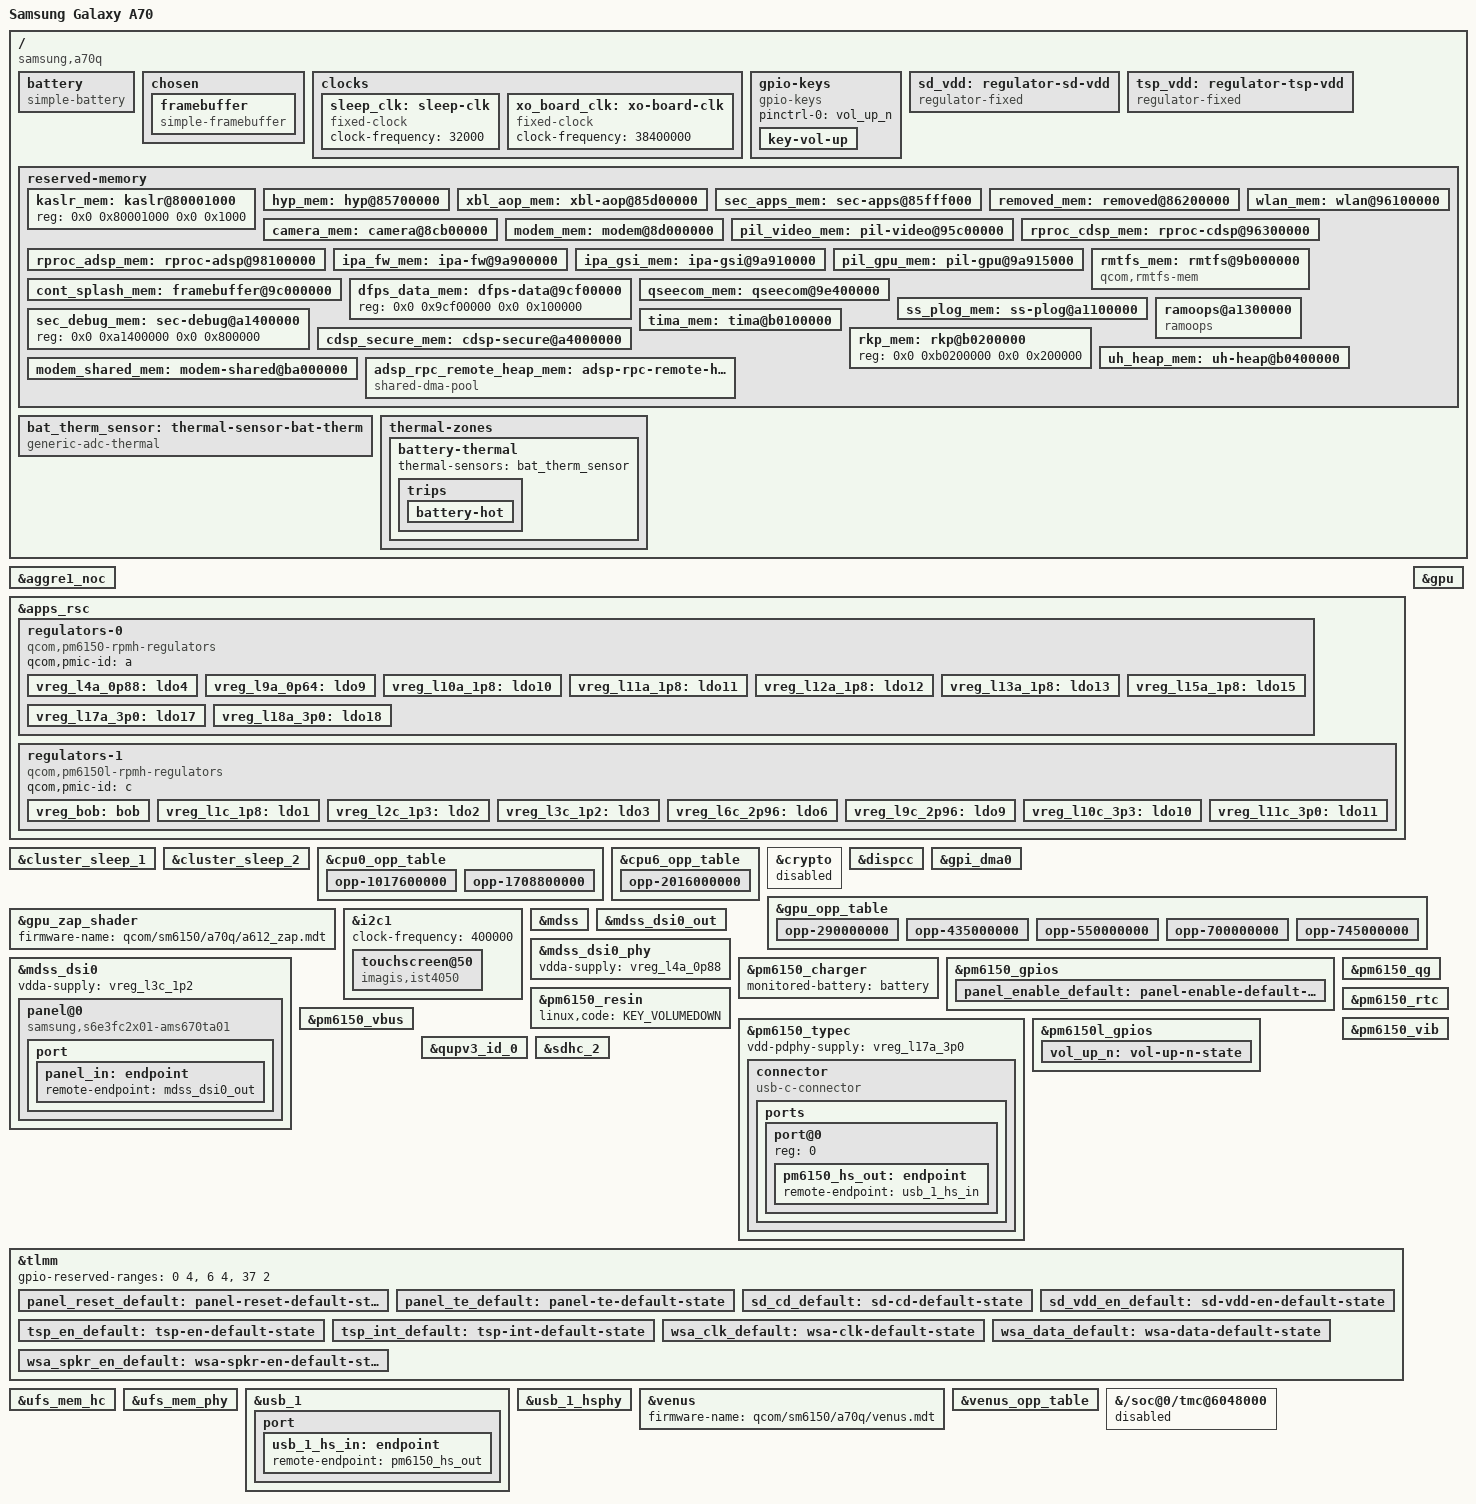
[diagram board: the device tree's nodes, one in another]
// SPDX-License-Identifier: BSD-3-Clause

/dts-v1/;

#include <dt-bindings/firmware/qcom,scm.h>
#include <dt-bindings/gpio/gpio.h>
#include <dt-bindings/interrupt-controller/irq.h>
#include <dt-bindings/regulator/qcom,rpmh-regulator.h>
#include <dt-bindings/sound/qcom,q6dsp-lpass-ports.h>
#include <dt-bindings/sound/qcom,q6asm.h>
#include "sm6150.dtsi"
#include "pm6150.dtsi"
#include "pm6150l.dtsi"

/delete-node/ &pil_video_mem;
/delete-node/ &rproc_cdsp_mem;
/delete-node/ &rproc_adsp_mem;
/delete-node/ &pil_gpu_mem;
/delete-node/ &adsp_rpc_remote_heap_mem;

/ {
	model = "Samsung Galaxy A70";
	compatible = "samsung,a70q", "qcom,sm6150";
	chassis-type = "handset";
	/* Required for the Samsung bootloader to select this DTB. */
	qcom,msm-id = <355 0>;
	qcom,board-id = <0x22 0x0e>;

	battery: battery {
		compatible = "simple-battery";
		device-chemistry = "lithium-ion";
		charge-full-design-microamp-hours = <4400000>;
		voltage-min-design-microvolt = <3400000>;
		voltage-max-design-microvolt = <4350000>;
		constant-charge-current-max-microamp = <1500000>;
		constant-charge-voltage-max-microvolt = <4350000>;
		charge-term-current-microamp = <250000>;
		re-charge-voltage-microvolt = <4280000>;
		operating-range-celsius = <0 50>;
		/* Measured on the device: 177 mV drop for a 0.5 A load step at ~5% and 30 C */
		factory-internal-resistance-micro-ohms = <350000>;
		ocv-capacity-celsius = <25>;
		ocv-capacity-table-0 = <4286500 100>, <4259000 98>,
				       <4233300 96>, <4209800 94>, <4188400 92>,
				       <4167700 90>, <4146400 88>, <4125300 86>,
				       <4106700 84>, <4092200 82>, <4077000 80>,
				       <4054400 78>, <4024000 76>, <3999800 74>,
				       <3984800 72>, <3972600 70>, <3961000 68>,
				       <3950400 66>, <3938400 64>, <3921000 62>,
				       <3899800 60>, <3880900 58>, <3864000 56>,
				       <3849400 54>, <3838300 52>, <3829100 50>,
				       <3820800 48>, <3813200 46>, <3806100 44>,
				       <3799600 42>, <3793500 40>, <3788000 38>,
				       <3783100 36>, <3778600 34>, <3774100 32>,
				       <3769900 30>, <3765200 28>, <3759300 26>,
				       <3752300 24>, <3744800 22>, <3736800 20>,
				       <3727600 18>, <3715600 16>, <3701400 14>,
				       <3692300 12>, <3687300 10>, <3685600 9>,
				       <3683800 8>, <3680800 7>, <3674200 6>,
				       <3652900 5>, <3608300 4>, <3549000 3>,
				       <3468800 2>, <3344200 1>, <2827900 0>;
	};

	chosen {
		ranges;
		#address-cells = <2>;
		#size-cells = <2>;

		framebuffer {
			compatible = "simple-framebuffer";
			memory-region = <&cont_splash_mem>;
			width = <1080>;
			height = <2400>;
			stride = <(1080 * 4)>;
			format = "a8r8g8b8";
			clocks = <&gcc GCC_DISP_HF_AXI_CLK>;
		};
	};

	clocks {
		sleep_clk: sleep-clk {
			compatible = "fixed-clock";
			clock-frequency = <32000>;
			#clock-cells = <0>;
		};

		xo_board_clk: xo-board-clk {
			compatible = "fixed-clock";
			clock-frequency = <38400000>;
			#clock-cells = <0>;
		};
	};

	gpio-keys {
		compatible = "gpio-keys";
		pinctrl-0 = <&vol_up_n>;
		pinctrl-names = "default";

		key-vol-up {
			label = "Volume Up";
			gpios = <&pm6150l_gpios 8 GPIO_ACTIVE_LOW>;
			debounce-interval = <15>;
			wakeup-source;
			linux,code = <KEY_VOLUMEUP>;
			linux,can-disable;
		};
	};

	/* Load switch between L9C and the microSD slot. */
	sd_vdd: regulator-sd-vdd {
		compatible = "regulator-fixed";
		regulator-name = "sd-vdd";
		regulator-min-microvolt = <2960000>;
		regulator-max-microvolt = <2960000>;
		gpio = <&tlmm 121 GPIO_ACTIVE_HIGH>;
		enable-active-high;
		vin-supply = <&vreg_l9c_2p96>;
		pinctrl-0 = <&sd_vdd_en_default>;
		pinctrl-names = "default";
	};

	tsp_vdd: regulator-tsp-vdd {
		compatible = "regulator-fixed";
		regulator-name = "tsp-vdd";
		regulator-min-microvolt = <3000000>;
		regulator-max-microvolt = <3000000>;
		gpio = <&tlmm 93 GPIO_ACTIVE_HIGH>;
		enable-active-high;
		pinctrl-0 = <&tsp_en_default>;
		pinctrl-names = "default";
	};

	reserved-memory {
		kaslr_mem: kaslr@80001000 {
			reg = <0x0 0x80001000 0x0 0x1000>;
		};

		hyp_mem: hyp@85700000 {
			reg = <0x0 0x85700000 0x0 0x600000>;
			no-map;
		};

		/* The AOP command DB occupies the final 128 KiB. */
		xbl_aop_mem: xbl-aop@85d00000 {
			reg = <0x0 0x85d00000 0x0 0x220000>;
			no-map;
		};

		sec_apps_mem: sec-apps@85fff000 {
			reg = <0x0 0x85fff000 0x0 0x1000>;
			no-map;
		};

		removed_mem: removed@86200000 {
			reg = <0x0 0x86200000 0x0 0x5600000>;
			no-map;
		};

		camera_mem: camera@8cb00000 {
			reg = <0x0 0x8cb00000 0x0 0x500000>;
			no-map;
		};

		modem_mem: modem@8d000000 {
			reg = <0x0 0x8d000000 0x0 0x8c00000>;
			no-map;
		};

		pil_video_mem: pil-video@95c00000 {
			reg = <0x0 0x95c00000 0x0 0x500000>;
			no-map;
		};

		wlan_mem: wlan@96100000 {
			reg = <0x0 0x96100000 0x0 0x200000>;
			no-map;
		};

		rproc_cdsp_mem: rproc-cdsp@96300000 {
			reg = <0x0 0x96300000 0x0 0x1e00000>;
			no-map;
		};

		rproc_adsp_mem: rproc-adsp@98100000 {
			reg = <0x0 0x98100000 0x0 0x2800000>;
			no-map;
		};

		ipa_fw_mem: ipa-fw@9a900000 {
			reg = <0x0 0x9a900000 0x0 0x10000>;
			no-map;
		};

		ipa_gsi_mem: ipa-gsi@9a910000 {
			reg = <0x0 0x9a910000 0x0 0x5000>;
			no-map;
		};

		pil_gpu_mem: pil-gpu@9a915000 {
			reg = <0x0 0x9a915000 0x0 0x2000>;
			no-map;
		};

		rmtfs_mem: rmtfs@9b000000 {
			compatible = "qcom,rmtfs-mem";
			reg = <0x0 0x9b000000 0x0 0x202000>;
			no-map;
			qcom,client-id = <1>;
			qcom,use-guard-pages;
			qcom,vmid = <QCOM_SCM_VMID_MSS_MSA>;
		};

		cont_splash_mem: framebuffer@9c000000 {
			reg = <0x0 0x9c000000 0x0 0xf00000>;
			no-map;
		};

		dfps_data_mem: dfps-data@9cf00000 {
			reg = <0x0 0x9cf00000 0x0 0x100000>;
		};

		qseecom_mem: qseecom@9e400000 {
			reg = <0x0 0x9e400000 0x0 0x2400000>;
			no-map;
		};

		ss_plog_mem: ss-plog@a1100000 {
			reg = <0x0 0xa1100000 0x0 0x200000>;
			no-map;
		};

		ramoops@a1300000 {
			compatible = "ramoops";
			reg = <0x0 0xa1300000 0x0 0x100000>;
			record-size = <0x40000>;
			console-size = <0x40000>;
			ftrace-size = <0x40000>;
			pmsg-size = <0x40000>;
		};

		/* The bootloader places the FDT inside this reservation. */
		sec_debug_mem: sec-debug@a1400000 {
			reg = <0x0 0xa1400000 0x0 0x800000>;
		};

		cdsp_secure_mem: cdsp-secure@a4000000 {
			reg = <0x0 0xa4000000 0x0 0xc00000>;
			no-map;
		};

		tima_mem: tima@b0100000 {
			reg = <0x0 0xb0100000 0x0 0x100000>;
			no-map;
		};

		rkp_mem: rkp@b0200000 {
			reg = <0x0 0xb0200000 0x0 0x200000>;
		};

		/*
		 * Heap of the Samsung hypervisor (uH) in the hyp partition. The
		 * stock bootloader adds this node at runtime; the CPU that
		 * touches it hangs.
		 */
		uh_heap_mem: uh-heap@b0400000 {
			reg = <0x0 0xb0400000 0x0 0x1400000>;
			no-map;
		};

		modem_shared_mem: modem-shared@ba000000 {
			reg = <0x0 0xba000000 0x0 0x6000000>;
			no-map;
		};

		/* Keep the remote heap at the address assigned by Samsung's QHEE. */
		adsp_rpc_remote_heap_mem: adsp-rpc-remote-heap@ef000000 {
			compatible = "shared-dma-pool";
			reg = <0x0 0xef000000 0x0 0x800000>;
			no-map;
		};
	};

	bat_therm_sensor: thermal-sensor-bat-therm {
		compatible = "generic-adc-thermal";
		#thermal-sensor-cells = <0>;
		#io-channel-cells = <0>;
		io-channels = <&pm6150_adc ADC5_BAT_THERM_100K_PU>;
		io-channel-names = "sensor-channel";
		/* 100 kOhm (B=4250K) NTC with a 1.875 V reference and 100 kOhm pull-up */
		temperature-lookup-table = <
					    (-40000) 1840
					    (-38000) 1835
					    (-36000) 1828
					    (-34000) 1821
					    (-32000) 1813
					    (-30000) 1803
					    (-28000) 1793
					    (-26000) 1781
					    (-24000) 1768
					    (-22000) 1753
					    (-20000) 1737
					    (-18000) 1719
					    (-16000) 1700
					    (-14000) 1679
					    (-12000) 1655
					    (-10000) 1630
					    (-8000) 1603
					    (-6000) 1574
					    (-4000) 1543
					    (-2000) 1510
					    0 1475
					    2000 1438
					    4000 1400
					    6000 1360
					    8000 1318
					    10000 1276
					    12000 1232
					    14000 1187
					    16000 1142
					    18000 1097
					    20000 1051
					    22000 1005
					    24000 960
					    26000 915
					    28000 871
					    30000 828
					    32000 786
					    34000 745
					    36000 705
					    38000 666
					    40000 629
					    42000 594
					    44000 560
					    46000 527
					    48000 497
					    50000 467
					    52000 439
					    54000 413
					    56000 388
					    58000 365
					    60000 343
					    62000 322
					    64000 302
					    66000 284
					    68000 267
					    70000 251
					    72000 235
					    74000 221
					    76000 208
					    78000 195
					    80000 184
					    82000 173
					    84000 163
					    86000 153
					    88000 144
					    90000 136
					    92000 128
					    94000 120
					    96000 114
					    98000 107
					    >;
	};

	thermal-zones {
		battery-thermal {
			thermal-sensors = <&bat_therm_sensor>;

			trips {
				battery-hot {
					temperature = <50000>;
					hysteresis = <2000>;
					type = "hot";
				};
			};
		};
	};

};

/*
 * The Samsung firmware describes no fabric-level A1 NoC QoS clocks, and
 * enabling the QCS615 provider clocks hangs the boot before rootfs mount.
 * Without clocks the interconnect driver skips QoS programming.
 */
&aggre1_noc {
	/delete-property/ clocks;
};

&apps_rsc {
	regulators-0 {
		compatible = "qcom,pm6150-rpmh-regulators";
		qcom,pmic-id = "a";

		vreg_l4a_0p88: ldo4 {
			regulator-name = "vreg_l4a_0p88";
			regulator-min-microvolt = <875000>;
			regulator-max-microvolt = <975000>;
			regulator-initial-mode = <RPMH_REGULATOR_MODE_HPM>;
		};

		vreg_l9a_0p64: ldo9 {
			regulator-name = "vreg_l9a_0p64";
			regulator-min-microvolt = <640000>;
			regulator-max-microvolt = <640000>;
			regulator-initial-mode = <RPMH_REGULATOR_MODE_HPM>;
		};

		vreg_l10a_1p8: ldo10 {
			regulator-name = "vreg_l10a_1p8";
			regulator-min-microvolt = <1800000>;
			regulator-max-microvolt = <1800000>;
			regulator-initial-mode = <RPMH_REGULATOR_MODE_HPM>;
		};

		vreg_l11a_1p8: ldo11 {
			regulator-name = "vreg_l11a_1p8";
			regulator-min-microvolt = <1800000>;
			regulator-max-microvolt = <1890000>;
			regulator-initial-mode = <RPMH_REGULATOR_MODE_HPM>;
		};

		vreg_l12a_1p8: ldo12 {
			regulator-name = "vreg_l12a_1p8";
			regulator-min-microvolt = <1800000>;
			regulator-max-microvolt = <1950000>;
			regulator-initial-mode = <RPMH_REGULATOR_MODE_HPM>;
		};

		vreg_l13a_1p8: ldo13 {
			regulator-name = "vreg_l13a_1p8";
			regulator-min-microvolt = <1800000>;
			regulator-max-microvolt = <1900000>;
			regulator-initial-mode = <RPMH_REGULATOR_MODE_HPM>;
		};

		vreg_l15a_1p8: ldo15 {
			regulator-name = "vreg_l15a_1p8";
			regulator-min-microvolt = <1800000>;
			regulator-max-microvolt = <1800000>;
			regulator-initial-mode = <RPMH_REGULATOR_MODE_HPM>;
		};

		vreg_l17a_3p0: ldo17 {
			regulator-name = "vreg_l17a_3p0";
			regulator-min-microvolt = <3000000>;
			regulator-max-microvolt = <3230000>;
			regulator-initial-mode = <RPMH_REGULATOR_MODE_HPM>;
		};

		vreg_l18a_3p0: ldo18 {
			regulator-name = "vreg_l18a_3p0";
			regulator-min-microvolt = <3000000>;
			regulator-max-microvolt = <3000000>;
			regulator-initial-mode = <RPMH_REGULATOR_MODE_HPM>;
		};
	};

	regulators-1 {
		compatible = "qcom,pm6150l-rpmh-regulators";
		qcom,pmic-id = "c";

		vreg_bob: bob {
			regulator-name = "vreg_bob";
			regulator-min-microvolt = <3008000>;
			regulator-max-microvolt = <3960000>;
			regulator-initial-mode = <RPMH_REGULATOR_MODE_AUTO>;
		};

		vreg_l1c_1p8: ldo1 {
			regulator-name = "vreg_l1c_1p8";
			regulator-min-microvolt = <1800000>;
			regulator-max-microvolt = <1900000>;
			regulator-initial-mode = <RPMH_REGULATOR_MODE_HPM>;
		};

		vreg_l2c_1p3: ldo2 {
			regulator-name = "vreg_l2c_1p3";
			regulator-min-microvolt = <1304000>;
			regulator-max-microvolt = <1304000>;
			regulator-initial-mode = <RPMH_REGULATOR_MODE_HPM>;
		};

		vreg_l3c_1p2: ldo3 {
			regulator-name = "vreg_l3c_1p2";
			regulator-min-microvolt = <1232000>;
			regulator-max-microvolt = <1260000>;
			regulator-initial-mode = <RPMH_REGULATOR_MODE_HPM>;
			regulator-always-on;
		};

		vreg_l6c_2p96: ldo6 {
			regulator-name = "vreg_l6c_2p96";
			regulator-min-microvolt = <1800000>;
			regulator-max-microvolt = <2960000>;
			regulator-initial-mode = <RPMH_REGULATOR_MODE_HPM>;
		};

		vreg_l9c_2p96: ldo9 {
			regulator-name = "vreg_l9c_2p96";
			regulator-min-microvolt = <2960000>;
			regulator-max-microvolt = <2960000>;
			regulator-initial-mode = <RPMH_REGULATOR_MODE_HPM>;
		};

		vreg_l10c_3p3: ldo10 {
			regulator-name = "vreg_l10c_3p3";
			regulator-min-microvolt = <3312000>;
			regulator-max-microvolt = <3312000>;
			regulator-initial-mode = <RPMH_REGULATOR_MODE_HPM>;
		};

		vreg_l11c_3p0: ldo11 {
			regulator-name = "vreg_l11c_3p0";
			regulator-min-microvolt = <2950000>;
			regulator-max-microvolt = <3312000>;
			regulator-initial-mode = <RPMH_REGULATOR_MODE_HPM>;
		};
	};
};

/*
 * The A70 firmware uses different CX-retention and LLCC-off PSCI parameters
 * and entry latencies than QCS615.
 */
&cluster_sleep_1 {
	entry-latency-us = <3638>;
	arm,psci-suspend-param = <0x41001244>;
};

&cluster_sleep_2 {
	entry-latency-us = <3263>;
	arm,psci-suspend-param = <0x4100b244>;
};

/* Match the OPPs programmed by the A70 firmware's cpufreq hardware LUT. */
&cpu0_opp_table {
	/delete-node/ opp-998400000;

	opp-1017600000 {
		opp-hz = /bits/ 64 <1017600000>;
		opp-peak-kBps = <(451000 * 4) (806400 * 16)>;
	};

	opp-1708800000 {
		opp-hz = /bits/ 64 <1708800000>;
		opp-peak-kBps = <(1017000 * 4) (1363200 * 16)>;
	};
};

&cpu6_opp_table {
	/delete-node/ opp-1094400000;

	opp-2016000000 {
		opp-hz = /bits/ 64 <2016000000>;
		opp-peak-kBps = <(1555000 * 4) (1363200 * 16)>;
	};
};

/*
 * The QCE driver depends on BROKEN, so nothing binds this node, and its
 * interconnect providers would never reach sync_state(): DDR would stay
 * at the boot-time maximum, also in the sleep set.
 */
&crypto {
	status = "disabled";
};

&dispcc {
	status = "okay";
};

&gpi_dma0 {
	status = "okay";
};

&gpu {
	status = "okay";
};

/* Match the speed bin and bus levels selected by the Samsung firmware. */
&gpu_opp_table {
	/delete-node/ opp-845000000;
	/delete-node/ opp-745000000;
	/delete-node/ opp-650000000;
	/delete-node/ opp-500000000;
	/delete-node/ opp-435000000;

	opp-290000000 {
		opp-hz = /bits/ 64 <290000000>;
		required-opps = <&rpmhpd_opp_low_svs>;
		opp-peak-kBps = <1804000>;
	};

	opp-435000000 {
		opp-hz = /bits/ 64 <435000000>;
		required-opps = <&rpmhpd_opp_svs>;
		opp-peak-kBps = <3000000>;
	};

	opp-550000000 {
		opp-hz = /bits/ 64 <550000000>;
		required-opps = <&rpmhpd_opp_svs_l1>;
		opp-peak-kBps = <3975000>;
	};

	opp-700000000 {
		opp-hz = /bits/ 64 <700000000>;
		required-opps = <&rpmhpd_opp_nom>;
		opp-peak-kBps = <5287500>;
	};

	opp-745000000 {
		opp-hz = /bits/ 64 <745000000>;
		required-opps = <&rpmhpd_opp_nom_l1>;
		opp-peak-kBps = <7050000>;
	};
};

&gpu_zap_shader {
	firmware-name = "qcom/sm6150/a70q/a612_zap.mdt";
};

&i2c1 {
	clock-frequency = <400000>;

	status = "okay";

	touchscreen@50 {
		compatible = "imagis,ist4050";
		reg = <0x50>;
		interrupt-parent = <&tlmm>;
		interrupts = <89 IRQ_TYPE_EDGE_FALLING>;
		vdd-supply = <&tsp_vdd>;
		vddio-supply = <&tsp_vdd>;
		pinctrl-0 = <&tsp_int_default>;
		pinctrl-names = "default";
		touchscreen-size-x = <1080>;
		touchscreen-size-y = <2400>;
	};
};

&mdss {
	status = "okay";
};

&mdss_dsi0 {
	vdda-supply = <&vreg_l3c_1p2>;

	status = "okay";

	panel@0 {
		compatible = "samsung,s6e3fc2x01-ams670ta01",
			     "samsung,s6e3fc2x01";
		reg = <0>;
		enable-gpios = <&pm6150_gpios 6 GPIO_ACTIVE_HIGH>;
		reset-gpios = <&tlmm 91 GPIO_ACTIVE_LOW>;
		te-gpios = <&tlmm 90 GPIO_ACTIVE_HIGH>;
		vddio-supply = <&vreg_l13a_1p8>;
		vci-supply = <&vreg_l18a_3p0>;
		pinctrl-0 = <&panel_enable_default>, <&panel_reset_default>,
			    <&panel_te_default>;
		pinctrl-names = "default";

		port {
			panel_in: endpoint {
				remote-endpoint = <&mdss_dsi0_out>;
			};
		};
	};
};

&mdss_dsi0_out {
	data-lanes = <0 1 2 3>;
	remote-endpoint = <&panel_in>;
};

&mdss_dsi0_phy {
	vdda-supply = <&vreg_l4a_0p88>;

	status = "okay";
};

&pm6150_charger {
	monitored-battery = <&battery>;

	status = "okay";
};

&pm6150_gpios {
	panel_enable_default: panel-enable-default-state {
		pins = "gpio6";
		function = "normal";
		power-source = <0>;
		bias-disable;
	};
};

&pm6150_qg {
	io-channels = <&bat_therm_sensor>;
	io-channel-names = "batt-therm";
	monitored-battery = <&battery>;
	power-supplies = <&pm6150_charger>;

	status = "okay";
};

&pm6150_resin {
	linux,code = <KEY_VOLUMEDOWN>;

	status = "okay";
};

&pm6150_rtc {
	status = "okay";
};

&pm6150_typec {
	vdd-pdphy-supply = <&vreg_l17a_3p0>;

	status = "okay";

	connector {
		compatible = "usb-c-connector";
		power-role = "dual";
		data-role = "dual";
		try-power-role = "sink";
		typec-power-opmode = "1.5A";
		self-powered;
		pd-disable;
		vbus-supply = <&pm6150_vbus>;

		ports {
			#address-cells = <1>;
			#size-cells = <0>;

			port@0 {
				reg = <0>;

				pm6150_hs_out: endpoint {
					remote-endpoint = <&usb_1_hs_in>;
				};
			};
		};
	};
};

&pm6150_vbus {
	regulator-min-microamp = <500000>;
	regulator-max-microamp = <1500000>;

	status = "okay";
};

&pm6150_vib {
	status = "okay";
};

&pm6150l_gpios {
	vol_up_n: vol-up-n-state {
		pins = "gpio8";
		function = "normal";
		power-source = <0>;
		bias-pull-up;
		input-enable;
	};
};

&qupv3_id_0 {
	status = "okay";
};

&sdhc_2 {
	pinctrl-0 = <&sdc2_state_on>, <&sd_cd_default>;
	pinctrl-1 = <&sdc2_state_off>, <&sd_cd_default>;
	pinctrl-names = "default", "sleep";
	bus-width = <4>;
	cd-gpios = <&tlmm 99 GPIO_ACTIVE_HIGH>;
	vmmc-supply = <&sd_vdd>;
	vqmmc-supply = <&vreg_l6c_2p96>;

	status = "okay";
};

&tlmm {
	/* These pins are assigned to secure-world peripherals by the firmware. */
	gpio-reserved-ranges = <0 4>, <6 4>, <37 2>;

	panel_reset_default: panel-reset-default-state {
		pins = "gpio91";
		function = "gpio";
		drive-strength = <8>;
		bias-disable;
	};

	panel_te_default: panel-te-default-state {
		pins = "gpio90";
		function = "mdp_vsync";
		drive-strength = <2>;
		bias-pull-down;
	};

	sd_cd_default: sd-cd-default-state {
		pins = "gpio99";
		function = "gpio";
		drive-strength = <2>;
		bias-disable;
	};

	sd_vdd_en_default: sd-vdd-en-default-state {
		pins = "gpio121";
		function = "gpio";
		drive-strength = <2>;
		bias-disable;
	};

	tsp_en_default: tsp-en-default-state {
		pins = "gpio93";
		function = "gpio";
		drive-strength = <2>;
		bias-pull-down;
	};

	tsp_int_default: tsp-int-default-state {
		pins = "gpio89";
		function = "gpio";
		drive-strength = <2>;
		bias-disable;
	};

	wsa_clk_default: wsa-clk-default-state {
		pins = "gpio111";
		function = "wsa_clk";
		drive-strength = <2>;
		bias-bus-hold;
	};

	wsa_data_default: wsa-data-default-state {
		pins = "gpio110";
		function = "wsa_data";
		drive-strength = <4>;
		bias-bus-hold;
	};

	wsa_spkr_en_default: wsa-spkr-en-default-state {
		pins = "gpio108";
		function = "gpio";
		drive-strength = <16>;
		bias-disable;
	};
};

&ufs_mem_hc {
	reset-gpios = <&tlmm 123 GPIO_ACTIVE_LOW>;
	vcc-supply = <&vreg_l11c_3p0>;
	vcc-max-microamp = <600000>;
	vccq2-supply = <&vreg_l12a_1p8>;
	vccq2-max-microamp = <600000>;

	status = "okay";
};

&ufs_mem_phy {
	vdda-phy-supply = <&vreg_l4a_0p88>;
	vdda-pll-supply = <&vreg_l11a_1p8>;

	status = "okay";
};

&usb_1 {
	dr_mode = "otg";
	maximum-speed = "high-speed";
	phys = <&usb_1_hsphy>;
	phy-names = "usb2-phy";
	usb-role-switch;
	qcom,select-utmi-as-pipe-clk;

	status = "okay";

	port {
		usb_1_hs_in: endpoint {
			remote-endpoint = <&pm6150_hs_out>;
		};
	};
};

&usb_1_hsphy {
	vdd-supply = <&vreg_l4a_0p88>;
	vdda-phy-dpdm-supply = <&vreg_l17a_3p0>;
	vdda-pll-supply = <&vreg_l11a_1p8>;

	status = "okay";
};

&venus {
	firmware-name = "qcom/sm6150/a70q/venus.mdt";

	status = "okay";
};

/* The A70 firmware does not expose the 460 MHz video clock level. */
&venus_opp_table {
	/delete-node/ opp-460000000;
};

/* The retail firmware gives the ETR no non-secure access. */
&{/soc@0/tmc@6048000} {
	status = "disabled";
};
